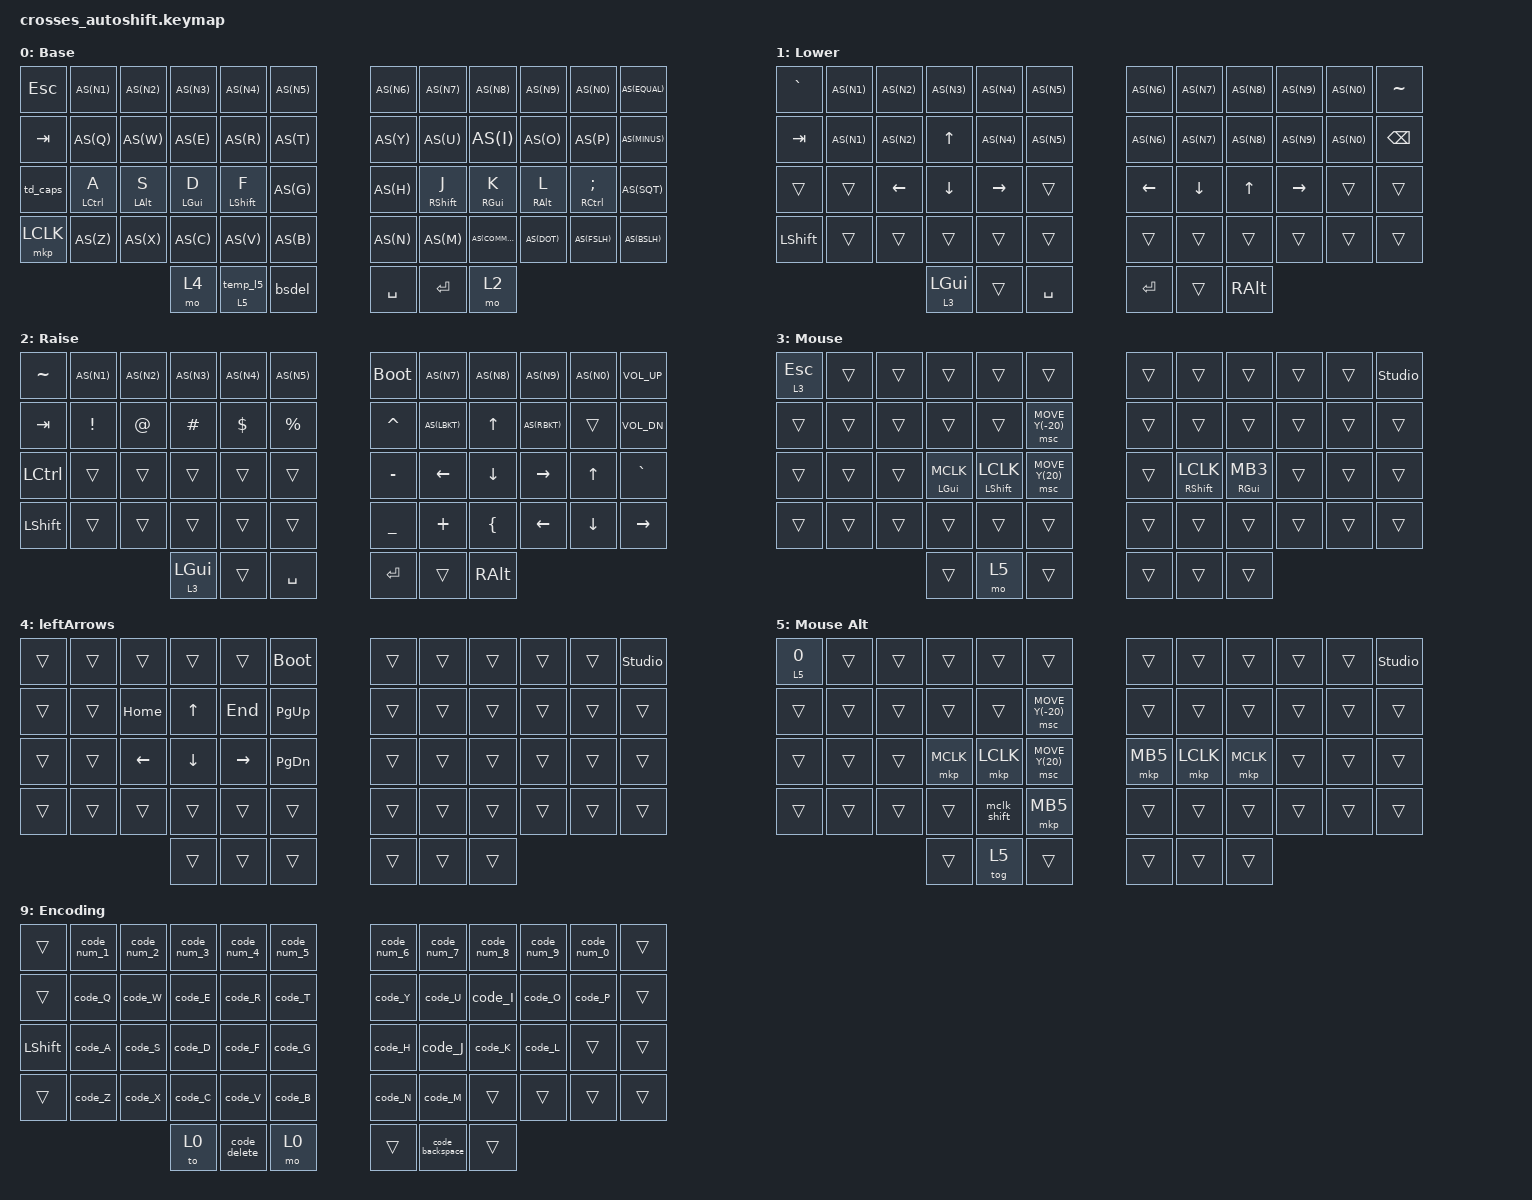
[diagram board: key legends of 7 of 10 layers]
// Референсная версия с автошифтом.
// Чтобы использовать, скопируй этот файл поверх config/crosses.keymap.
// Keymap Editor макросы не парсит, поэтому по умолчанию активна версия без AS().
#include "keys_ru.h"
#include <behaviors.dtsi>
#include <dt-bindings/zmk/bt.h>
#include <dt-bindings/zmk/keys.h>
#include <dt-bindings/zmk/pointing.h>
#include <input/processors.dtsi>
#include <dt-bindings/zmk/mouse.h>
#include <zephyr/dt-bindings/input/input-event-codes.h>

#define ZB0 #binding-cells = <0>
#define MODS_FOR_AS (MOD_LGUI|MOD_RGUI|MOD_LALT|MOD_RALT|MOD_LCTL|MOD_RCTL)

#define MOD_MORPH_AS(keycode) \
    as_##keycode: as_##keycode { \
        compatible = "zmk,behavior-mod-morph"; \
        ZB0; \
        bindings = <&as LS(keycode) keycode>, <&kp keycode>; \
        mods = <MODS_FOR_AS>; \
        keep-mods = <MODS_FOR_AS>; \
    };

#define AS(keycode) &as_##keycode

&trackball_peripheral_split {
    input-processors
        = <&zip_ble_report_rate_limit>;
};


/ {
    /omit-if-no-ref/ zip_temp_layer: zip_temp_layer {
        compatible = "zmk,input-processor-temp-layer";
        #input-processor-cells = <2>;
        require-prior-idle-ms = <500>;
        //excluded-positions = <1 2 3>;
    };
};

&trackball_central_listener {
    input-processors = <&zip_temp_layer 3 350>, <&zip_ble_report_rate_limit>;
};
&msc {
    x-input-code = <INPUT_REL_HWHEEL>;
    y-input-code = <INPUT_REL_WHEEL>;
    time-to-max-speed-ms = <800>;
    acceleration-exponent = <5>;
    trigger-period-ms = <8>;
};
/ {
    chosen { zmk,physical-layout = &gggw_crosses_54_layout; };

    behaviors {
        as: auto_shift {
            compatible = "zmk,behavior-hold-tap";
            #binding-cells = <2>;
            tapping-term-ms = <150>;
            quick-tap-ms = <0>;
            require-prior-idle-ms = <125>;
            flavor = "tap-preferred";
            bindings = <&kp>, <&kp>;
        };
        MOD_MORPH_AS(Q)
        MOD_MORPH_AS(W)
        MOD_MORPH_AS(E)
        MOD_MORPH_AS(R)
        MOD_MORPH_AS(T)
        MOD_MORPH_AS(Y)
        MOD_MORPH_AS(U)
        MOD_MORPH_AS(I)
        MOD_MORPH_AS(O)
        MOD_MORPH_AS(P)
        MOD_MORPH_AS(G)
        MOD_MORPH_AS(H)
        MOD_MORPH_AS(Z)
        MOD_MORPH_AS(X)
        MOD_MORPH_AS(C)
        MOD_MORPH_AS(V)
        MOD_MORPH_AS(B)
        MOD_MORPH_AS(N)
        MOD_MORPH_AS(M)
        MOD_MORPH_AS(N0)
        MOD_MORPH_AS(N1)
        MOD_MORPH_AS(N2)
        MOD_MORPH_AS(N3)
        MOD_MORPH_AS(N4)
        MOD_MORPH_AS(N5)
        MOD_MORPH_AS(N6)
        MOD_MORPH_AS(N7)
        MOD_MORPH_AS(N8)
        MOD_MORPH_AS(N9)
        MOD_MORPH_AS(EQUAL)
        MOD_MORPH_AS(MINUS)
        MOD_MORPH_AS(SQT)
        MOD_MORPH_AS(COMMA)
        MOD_MORPH_AS(DOT)
        MOD_MORPH_AS(FSLH)
        MOD_MORPH_AS(BSLH)
        MOD_MORPH_AS(LBKT)
        MOD_MORPH_AS(RBKT)
        caps_lock_word: caps_lock_word {
            compatible = "zmk,behavior-caps-word";
            #binding-cells = <0>;
            continue-list = <UNDERSCORE MINUS BACKSPACE DELETE>;
        };
        td_caps: tap_dance_caps {
            compatible = "zmk,behavior-tap-dance";
            #binding-cells = <0>;
            tapping-term-ms = <250>;
            bindings = <&kp LSHFT>, <&caps_lock_word>;
        };
        mclk_shift: mclk_shift {
            compatible = "zmk,behavior-macro";
            #binding-cells = <0>;
            bindings = <&macro_press &kp LSHFT &mkp MCLK>,
                       <&macro_pause_for_release>,
                       <&macro_release &mkp MCLK &kp LSHFT>;
        };
        code_backspace: code_backspace {
            compatible = "zmk,behavior-macro";
            #binding-cells = <0>;
            bindings = <&kp BSPC &kp BSPC &kp BSPC &kp BSPC>;
        };
        code_delete: code_delete {
            compatible = "zmk,behavior-macro";
            #binding-cells = <0>;
            bindings = <&kp DEL &kp DEL &kp DEL &kp DEL>;
        };
        bsdel: backspace_delete {
            compatible = "zmk,behavior-mod-morph";
            #binding-cells = <0>;
            bindings = <&kp BSPC>, <&kp DEL>;
            mods = <(MOD_LSFT|MOD_RSFT)>;
        };
        hml: homerow_mod_left {
            compatible = "zmk,behavior-hold-tap";
            #binding-cells = <2>;
            flavor = "balanced";
            tapping-term-ms = <180>;
            require-prior-idle-ms = <125>;
            bindings = <&kp>, <&kp>;
            hold-trigger-key-positions = <6 7 8 9 10 11 18 19 20 21 22 23 30 31 32 33 34 35 39 40 41>;
            hold-trigger-on-release;
        };
        hmr: homerow_mod_right {
            compatible = "zmk,behavior-hold-tap";
            #binding-cells = <2>;
            flavor = "balanced";
            tapping-term-ms = <180>;
            require-prior-idle-ms = <125>;
            bindings = <&kp>, <&kp>;
            hold-trigger-key-positions = <0 1 2 3 4 5 12 13 14 15 16 17 24 25 26 27 28 29 36 37 38>;
            hold-trigger-on-release;
        };
        hml_s: homerow_mod_left_shift {
            compatible = "zmk,behavior-hold-tap";
            #binding-cells = <2>;
            flavor = "hold-preferred";
            tapping-term-ms = <180>;
            require-prior-idle-ms = <125>;
            bindings = <&kp>, <&kp>;
            hold-trigger-key-positions = <6 7 8 9 10 11 18 19 20 21 22 23 30 31 32 33 34 35 39 40 41>;
            hold-trigger-on-release;
        };
        hmr_s: homerow_mod_right_shift {
            compatible = "zmk,behavior-hold-tap";
            #binding-cells = <2>;
            flavor = "hold-preferred";
            tapping-term-ms = <180>;
            require-prior-idle-ms = <125>;
            bindings = <&kp>, <&kp>;
            hold-trigger-key-positions = <0 1 2 3 4 5 12 13 14 15 16 17 24 25 26 27 28 29 36 37 38>;
            hold-trigger-on-release;
        };
        temp_l5: temp_l5 {
            compatible = "zmk,behavior-macro";
            #binding-cells = <0>;
            wait-ms = <0>;
            tap-ms = <0>;
            bindings = <&tog 5 &macro_wait_time 3000 &tog 5>;
        };
        ht_mo5: ht_mo5 {
            compatible = "zmk,behavior-hold-tap";
            #binding-cells = <2>;
            flavor = "balanced";
            tapping-term-ms = <200>;
            bindings = <&mo>, <&temp_l5>;
        };
        mclk_gui: mclk_gui {
            compatible = "zmk,behavior-hold-tap";
            #binding-cells = <2>;
            flavor = "balanced";
            tapping-term-ms = <200>;
            bindings = <&kp>, <&mkp>;
        };
    };

    combos {
        compatible = "zmk,combos";

        num_lauer {
            bindings = <&mo 8>;
            key-positions = <50 49>;
            timeout-ms = <200>;
            require-prior-idle-ms = <100>;
            slow-release;
        };

        en_sym {
            bindings = <&mo 1>;
            key-positions = <48 49>;
            timeout-ms = <120>;
            require-prior-idle-ms = <200>;
            slow-release;
            layers = <0>;
        };

        lang {
            bindings = <&lg_tog>;
            key-positions = <36 50>;
            timeout-ms = <150>;
        };

        ru_sym {
            bindings = <&mo 7>;
            key-positions = <48 49>;
            timeout-ms = <120>;
            require-prior-idle-ms = <200>;
            slow-release;
            layers = <6>;
        };

        rclk_combom {
            bindings = <&mkp LCLK>;
            key-positions = <19 20>;
        };

        lclk {
            bindings = <&mkp RCLK>;
            key-positions = <19 21>;
        };

        terminal {
            bindings = <&kp LG(GRAVE)>;
            key-positions = <16 0>;
            timeout-ms = <150>;
            layers = <0 6>;
        };
    };

    macros {
        #include "encoding_macros.dtsi"

        many_money: many_money {
            compatible = "zmk,behavior-macro";
            #binding-cells = <0>;
            bindings = <&none &kp LS(D) &kp O &kp C &kp K &kp E &kp R &kp SPACE &kp C &kp O &kp M &kp P &kp O &kp S &kp E &kp SPACE &kp LS(U) &kp LS(P) &kp SPACE &kp MINUS &kp D &kp SPACE &kp N7 &kp N2 &kp N3 &kp N0 &kp N5>;
            label = "MANY_MONEY";
        };

        lg_tog: lg_tog {
            compatible = "zmk,behavior-macro";
            #binding-cells = <0>;
            label = "LG_TOG";
            bindings = <&kp LG(SPACE) &tog 6>;
            tap-ms = <30>;
            wait-ms = <0>;
        };

        to_ru: to_ru {
            compatible = "zmk,behavior-macro";
            #binding-cells = <0>;
            bindings = <&kp LG(SPACE)>;
            label = "TO_RU";
            wait-ms = <0>;
            tap-ms = <30>;
        };

        to_en: to_en {
            compatible = "zmk,behavior-macro";
            #binding-cells = <0>;
            bindings = <&kp LG(SPACE)>;
            label = "TO_EN";
            wait-ms = <0>;
            tap-ms = <30>;
        };

        layer_en: layer_en {
            compatible = "zmk,behavior-macro";
            #binding-cells = <0>;
            bindings = <&to 0 &to_en>;
            label = "LAYER_EN";
            wait-ms = <0>;
            tap-ms = <30>;
        };

        layer_ru: layer_ru {
            compatible = "zmk,behavior-macro";
            #binding-cells = <0>;
            bindings = <&to 6 &to_ru>;
            label = "LAYER_RU";
            tap-ms = <30>;
            wait-ms = <0>;
        };

        en: en {
            compatible = "zmk,behavior-macro-one-param";
            #binding-cells = <1>;
            bindings =
                <&to_en>,
                <&macro_press>,
                <&macro_param_1to1 &kp MACRO_PLACEHOLDER>,
                <&macro_pause_for_release>,
                <&macro_release>,
                <&macro_param_1to1 &kp MACRO_PLACEHOLDER>,
                <&macro_tap>,
                <&to_ru>;

            label = "EN";
            wait-ms = <0>;
            tap-ms = <30>;
        };
    };

    keymap {
        compatible = "zmk,keymap";
        default_layer {
            display-name = "Base";
            bindings = <
                &kp ESC         AS(N1)          AS(N2)          AS(N3)          AS(N4)          AS(N5)                      AS(N6)          AS(N7)          AS(N8)          AS(N9)          AS(N0)              AS(EQUAL)
                &kp TAB         AS(Q)           AS(W)           AS(E)           AS(R)           AS(T)                       AS(Y)           AS(U)           AS(I)           AS(O)           AS(P)               AS(MINUS)
                &td_caps        &hml LCTRL A    &hml LALT S     &hml LGUI D     &hml_s LSHFT F  AS(G)                       AS(H)           &hmr_s RSHFT J  &hmr RGUI K     &hmr RALT L     &hmr RCTRL SEMI     AS(SQT)
                &mkp LCLK       AS(Z)           AS(X)           AS(C)           AS(V)           AS(B)                       AS(N)           AS(M)           AS(COMMA)       AS(DOT)         AS(FSLH)            AS(BSLH)
                                                                &mo 4           &ht_mo5 5 0     &bsdel                      &kp SPACE       &kp RET         &mo 2
            >;
        }; 
        
        lower_layer {
            display-name = "Lower";
            bindings = <
                &kp GRAVE       AS(N1)          AS(N2)          AS(N3)          AS(N4)          AS(N5)                      AS(N6)          AS(N7)          AS(N8)          AS(N9)           AS(N0)             &kp TILDE
                &kp TAB         AS(N1)          AS(N2)          &kp UP          AS(N4)          AS(N5)                      AS(N6)          AS(N7)          AS(N8)          AS(N9)           AS(N0)             &kp BSPC
                &trans          &trans          &kp LEFT        &kp DOWN        &kp RIGHT       &trans                      &kp LEFT        &kp DOWN        &kp UP          &kp RIGHT        &trans             &trans
                &kp LSHFT       &trans          &trans          &trans          &trans          &trans                      &trans          &trans          &trans          &trans           &trans             &trans
                                                                &lt 3 LGUI      &trans          &kp SPACE                   &kp RET         &trans          &kp RALT

            >;
        };

        raise_layer {
            display-name = "Raise";
            bindings = <
                &kp TILDE       AS(N1)          AS(N2)          AS(N3)          AS(N4)          AS(N5)                      &bootloader     AS(N7)          AS(N8)          AS(N9)           AS(N0)             &kp C_VOL_UP
                &kp TAB         &kp EXCL        &kp AT          &kp HASH        &kp DLLR        &kp PRCNT                   &kp CARET       AS(LBKT)        &kp UP          AS(RBKT)         &trans             &kp C_VOL_DN
                &kp LCTRL       &trans          &trans          &trans          &trans          &trans                      &kp MINUS       &kp LEFT        &kp DOWN        &kp RIGHT        &kp UP             &kp GRAVE
                &kp LSHFT       &trans          &trans          &trans          &trans          &trans                      &kp UNDER       &kp PLUS        &kp LBRC        &kp LEFT         &kp DOWN           &kp RIGHT
                                                                &lt 3 LGUI      &trans          &kp SPACE                   &kp RET         &trans          &kp RALT
            >;
        };
        mouse_layer {
            display-name = "Mouse";
            bindings = <        
                &lt 3 ESC     &trans            &trans          &trans          &trans          &trans                      &trans          &trans          &trans          &trans           &trans             &studio_unlock
                &trans        &trans            &trans          &trans          &trans          &msc MOVE_Y(-20)            &trans          &trans          &trans          &trans           &trans             &trans
                &trans        &trans            &trans          &mclk_gui LGUI MCLK &mclk_gui LSHFT LCLK &msc MOVE_Y(20)    &trans          &mclk_gui RSHFT LCLK &mclk_gui RGUI MB3 &trans   &trans             &trans
                &trans        &trans            &trans          &trans          &trans          &trans                      &trans          &trans          &trans          &trans           &trans             &trans
                                                                &trans          &mo 5           &trans                      &trans          &trans          &trans
            >;
        };
        left_arrows {
            display-name = "leftArrows";
            bindings = <        
                &trans         &trans           &trans          &trans          &trans          &bootloader                 &trans          &trans          &trans          &trans          &trans              &studio_unlock
                &trans         &trans           &kp HOME        &kp UP          &kp END         &kp PG_UP                   &trans          &trans          &trans          &trans          &trans              &trans
                &trans         &trans           &kp LEFT        &kp DOWN        &kp RIGHT       &kp PG_DN                   &trans          &trans          &trans          &trans          &trans              &trans
                &trans         &trans           &trans          &trans          &trans          &trans                      &trans          &trans          &trans          &trans          &trans              &trans
                                                                &trans          &trans          &trans                      &trans          &trans          &trans
            >;
        };
        mouse_layer_alt {
            display-name = "Mouse Alt";
            bindings = <        
                &lt 5 0       &trans            &trans          &trans          &trans          &trans                      &trans          &trans          &trans          &trans           &trans             &studio_unlock
                &trans        &trans            &trans          &trans          &trans          &msc MOVE_Y(-20)            &trans          &trans          &trans          &trans           &trans             &trans
                &trans        &trans            &trans          &mkp MCLK       &mkp LCLK       &msc MOVE_Y(20)             &mkp MB5        &mkp LCLK       &mkp MCLK       &trans           &trans             &trans
                &trans        &trans            &trans          &trans          &mclk_shift     &mkp MB5                    &trans          &trans          &trans          &trans           &trans             &trans
                                                                &trans          &tog 5          &trans                      &trans          &trans          &trans
            >;
        };

        ru_layer {
            display-name = "Base RU";
            bindings = <
                &kp ESC         &kp RU_CYRILLIC_SHORT_I            &kp RU_CYRILLIC_TSE        &kp RU_CYRILLIC_U       &kp RU_CYRILLIC_KA      &kp RU_CYRILLIC_IE      &kp RU_CYRILLIC_EN  &kp RU_CYRILLIC_GHE  &kp RU_CYRILLIC_SHA    &kp RU_CYRILLIC_SHCHA  &kp RU_CYRILLIC_ZE    &kp RU_CYRILLIC_HA
                &kp TAB         &hml LCTRL RU_CYRILLIC_EF          &hml LALT RU_CYRILLIC_YERU &hml LGUI RU_CYRILLIC_VE &hml_s LSHFT RU_CYRILLIC_A &kp RU_CYRILLIC_PE  &kp RU_CYRILLIC_ER  &hmr_s RSHFT RU_CYRILLIC_O  &hmr RGUI RU_CYRILLIC_EL  &hmr RALT RU_CYRILLIC_DE  &hmr RCTRL RU_CYRILLIC_ZHE  &kp RU_CYRILLIC_E
                &mkp LCLK       &kp RU_CYRILLIC_YA                 &kp RU_CYRILLIC_CHE        &kp RU_CYRILLIC_ES      &kp RU_CYRILLIC_EM      &kp RU_CYRILLIC_I       &kp RU_CYRILLIC_TE  &kp RU_CYRILLIC_SOFT_SIGN   &kp RU_CYRILLIC_BE     &kp RU_CYRILLIC_YU       &kp RU_DOT                &kp RU_CYRILLIC_IO
                                                                &mo 4           &ht_mo5 5 0     &bsdel                      &kp SPACE       &kp RET         &mo 2
            >;
        };

        sym_ru_layer {
            display-name = "Sym RU";
            bindings = <
                &trans  &trans  &en CARET  &en LT    &en GT    &en GRAVE                     &kp UNDER     &kp MINUS    &kp EQUAL   &kp PLUS          &none        &trans
                &trans  &trans  &en TILDE  &en LBRC  &en RBRC  &kp RU_DQT                    &kp RU_COLON  &kp RU_SEMI  &en PIPE    &kp RU_BACKSLASH  &kp RU_FSLH  &kp EXCL
                &trans  &trans  &kp STAR   &kp LPAR  &kp RPAR  &kp RU_DQT                    &en AT        &kp PRCNT    &en AMPS    &en HASH          &kp DOLLAR   &kp RU_QMARK
                                            &trans   &trans    &trans    &trans      &trans    &trans  &trans        &trans       &kp RU_DOT  &kp RU_COMMA
            >;
        };

        numpad_layer {
            display-name = "Numpad";
            bindings = <
&to 0   &trans  &trans  &trans  &trans  &trans                             &kp N7  &kp N8  &kp N9  &kp N0        &kp KP_DIVIDE  &kp KP_NUMLOCK
&trans  &trans  &trans  &trans  &trans  &trans                             &kp N4  &kp N5  &kp N6  &kp KP_MINUS  &kp KP_PLUS    &kp EQUAL
&trans  &trans  &trans  &trans  &trans  &trans                             &kp N1  &kp N2  &kp N3  &kp KP_DOT    &trans         &trans
                &tog 6  &trans  &trans  &trans  &trans    &kp RIGHT_SHIFT  &trans  &trans  &trans  &trans
            >;
        };

        encoding_layer {
            display-name = "Encoding";
            bindings = <
&trans          &code_num_1  &code_num_2  &code_num_3  &code_num_4   &code_num_5  &code_num_6  &code_num_7      &code_num_8  &code_num_9  &code_num_0  &trans
&trans          &code_Q      &code_W      &code_E      &code_R       &code_T      &code_Y      &code_U          &code_I      &code_O      &code_P      &trans
&kp LEFT_SHIFT  &code_A      &code_S      &code_D      &code_F       &code_G      &code_H      &code_J          &code_K      &code_L      &trans       &trans
&trans          &code_Z      &code_X      &code_C      &code_V       &code_B      &code_N      &code_M          &trans       &trans       &trans       &trans
                                          &to 0        &code_delete  &mo 0        &trans       &code_backspace  &trans
            >;
        };
    };
};
